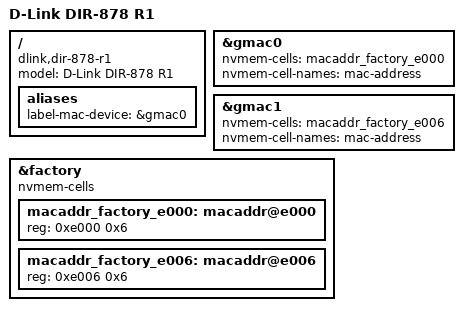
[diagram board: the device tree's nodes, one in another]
// SPDX-License-Identifier: GPL-2.0-or-later OR MIT

#include "mt7621_dlink_dir-8xx.dtsi"
#include "mt7621_dlink_flash-16m-r1.dtsi"

/ {
	compatible = "dlink,dir-878-r1", "mediatek,mt7621-soc";
	model = "D-Link DIR-878 R1";

	aliases {
		label-mac-device = &gmac0;
	};
};

&gmac0 {
	nvmem-cells = <&macaddr_factory_e000>;
	nvmem-cell-names = "mac-address";
};

&gmac1 {
	nvmem-cells = <&macaddr_factory_e006>;
	nvmem-cell-names = "mac-address";
};

&factory {
	compatible = "nvmem-cells";
	#address-cells = <1>;
	#size-cells = <1>;

	macaddr_factory_e000: macaddr@e000 {
		reg = <0xe000 0x6>;
	};

	macaddr_factory_e006: macaddr@e006 {
		reg = <0xe006 0x6>;
	};
};
